# MSP430FR2355 register map
Vendor: msp430gen; File version: v0.4.0-28-gb0087ce-dirty
Registers are 16-bit, read-write, reset 0x0 unless marked. A register's access mark holds for its fields unless they carry their own. Offsets are from the block's base; [hi:lo] are bit positions.

## P3
Base 0x00000220
0x00 P3IN 8-bit — Port 3 Input
0x02 P3OUT 8-bit — Port 3 Output
0x04 P3DIR 8-bit — Port 3 Direction
0x06 P3REN 8-bit — Port 3 Resistor Enable
0x0A P3SEL0 8-bit — Port 3 Select 0
0x0C P3SEL1 8-bit — Port 3 Select 1
0x0E P3IV — Port 3 Interrupt Vector Register
  [15:0] P3IV ro — Port 3 interrupt vector value
    0=NONE (No interrupt pending); 2=IFG0 (Interrupt Source: Port x.0 interrupt; Interrupt Flag: PxIFG.0; Interrupt Priority: Highest); 4=IFG1 (Interrupt Source: Port x.1 interrupt; Interrupt Flag: PxIFG.1); 6=IFG2 (Interrupt Source: Port x.2 interrupt; Interrupt Flag: PxIFG.2); 8=IFG3 (Interrupt Source: Port x.3 interrupt; Interrupt Flag: PxIFG.3); 10=IFG4 (Interrupt Source: Port x.4 interrupt; Interrupt Flag: PxIFG.4); 12=IFG5 (Interrupt Source: Port x.5 interrupt; Interrupt Flag: PxIFG.5); 14=IFG6 (Interrupt Source: Port x.6 interrupt; Interrupt Flag: PxIFG.6); 16=IFG7 (Interrupt Source: Port x.7 interrupt; Interrupt Flag: PxIFG.7; Interrupt Priority: Lowest)
0x16 P3SELC 8-bit — Port 3 Complement Select
0x18 P3IES 8-bit — Port 3 Interrupt Edge Select
0x1A P3IE 8-bit — Port 3 Interrupt Enable
0x1C P3IFG 8-bit — Port 3 Interrupt Flag

## P4
Base 0x00000220
0x01 P4IN 8-bit — Port 4 Input
0x03 P4OUT 8-bit — Port 4 Output
0x05 P4DIR 8-bit — Port 4 Direction
0x07 P4REN 8-bit — Port 4 Resistor Enable
0x0B P4SEL0 8-bit — Port 4 Select 0
0x0D P4SEL1 8-bit — Port 4 Select 1
0x17 P4SELC 8-bit — Port 4 Complement Select
0x19 P4IES 8-bit — Port 4 Interrupt Edge Select
0x1B P4IE 8-bit — Port 4 Interrupt Enable
0x1D P4IFG 8-bit — Port 4 Interrupt Flag
0x1E P4IV — Port 4 Interrupt Vector Register
  [15:0] P4IV ro — Port 4 interrupt vector value
    0=NONE (No interrupt pending); 2=IFG0 (Interrupt Source: Port x.0 interrupt; Interrupt Flag: PxIFG.0; Interrupt Priority: Highest); 4=IFG1 (Interrupt Source: Port x.1 interrupt; Interrupt Flag: PxIFG.1); 6=IFG2 (Interrupt Source: Port x.2 interrupt; Interrupt Flag: PxIFG.2); 8=IFG3 (Interrupt Source: Port x.3 interrupt; Interrupt Flag: PxIFG.3); 10=IFG4 (Interrupt Source: Port x.4 interrupt; Interrupt Flag: PxIFG.4); 12=IFG5 (Interrupt Source: Port x.5 interrupt; Interrupt Flag: PxIFG.5); 14=IFG6 (Interrupt Source: Port x.6 interrupt; Interrupt Flag: PxIFG.6); 16=IFG7 (Interrupt Source: Port x.7 interrupt; Interrupt Flag: PxIFG.7; Interrupt Priority: Lowest)

## P5
Base 0x00000240
0x00 P5IN 8-bit — Port 5 Input
0x02 P5OUT 8-bit — Port 5 Output
0x04 P5DIR 8-bit — Port 5 Direction
0x06 P5REN 8-bit — Port 5 Resistor Enable
0x0A P5SEL0 8-bit — Port 5 Select 0
0x0C P5SEL1 8-bit — Port 5 Select 1
0x16 P5SELC 8-bit — Port 5 Complement Select

## P6
Base 0x00000240
0x01 P6IN 8-bit — Port 6 Input
0x03 P6OUT 8-bit — Port 6 Output
0x05 P6DIR 8-bit — Port 6 Direction
0x07 P6REN 8-bit — Port 6 Resistor Enable
0x0B P6SEL0 8-bit — Port 6 Select 0
0x0D P6SEL1 8-bit — Port 6 Select 1
0x17 P6SELC 8-bit — Port 6 Complement Select

## SFR
Base 0x00000100
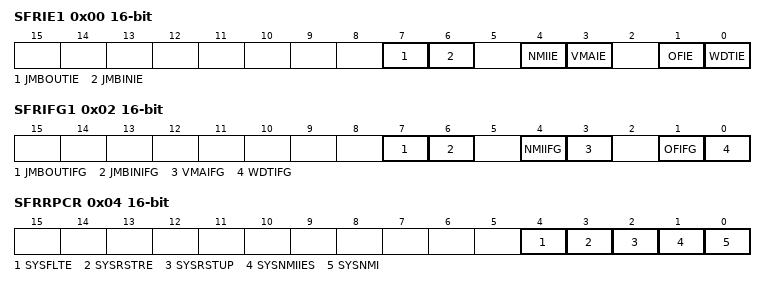
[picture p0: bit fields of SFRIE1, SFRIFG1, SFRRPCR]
0x00 SFRIE1 — Interrupt Enable
  [all] fields
    0=DISABLE (Interrupts disabled); 1=ENABLE (Interrupts enabled)
  [7] JMBOUTIE — JTAG mailbox output interrupt enable
  [6] JMBINIE — JTAG mailbox input interrupt enable
  [4] NMIIE — NMI pin interrupt enable
  [3] VMAIE — Vacant memory access interrupt enable
  [1] OFIE — Oscillator fault interrupt enable
  [0] WDTIE — Watchdog timer interrupt enable
0x02 SFRIFG1 — Interrupt Flag
  [7] JMBOUTIFG — JTAG mailbox output interrupt flag
    0=No interrupt pending. When in 16-bit mode (JMBMODE = 0), this bit is cleared automatically when JMBO0 has been written with a new message to the JTAG module by the CPU. When in 32-bit mode (JMBMODE = 1), this bit is cleared automatically when both JMBO0 and JMBO1 have been written with new messages to the JTAG module by the CPU. This bit is also cleared when the associated vector in SYSUNIV has been read.; 1=Interrupt pending. JMBO registers are ready for new messages. In 16-bit mode (JMBMODE = 0), JMBO0 has been received by the JTAG module and is ready for a new message from the CPU. In 32-bit mode (JMBMODE = 1), JMBO0 and JMBO1 have been received by the JTAG module and are ready for new messages from the CPU.
  [6] JMBINIFG — JTAG mailbox input interrupt flag
    0=No interrupt pending. When in 16-bit mode (JMBMODE = 0), this bit is cleared automatically when JMBI0 is read by the CPU. When in 32-bit mode (JMBMODE = 1), this bit is cleared automatically when both JMBI0 and JMBI1 have been read by the CPU. This bit is also cleared when the associated vector in SYSUNIV has been read; 1=Interrupt pending. A message is waiting in the JMBIN registers. In 16-bit mode (JMBMODE = 0) when JMBI0 has been written by the JTAG module. In 32-bit mode (JMBMODE = 1) when JMBI0 and JMBI1 have been written by the JTAG module.
  [4] NMIIFG — NMI pin interrupt flag
    0=No interrupt pending; 1=Interrupt pending
  [3] VMAIFG — Vacant memory access interrupt flag
    0=No interrupt pending; 1=Interrupt pending
  [1] OFIFG — Oscillator fault interrupt flag
    0=No interrupt pending; 1=Interrupt pending
  [0] WDTIFG — Watchdog timer interrupt flag
    0=No interrupt pending; 1=Interrupt pending
0x04 SFRRPCR — Reset Pin Control
  [4] SYSFLTE — Reset pin filter enable
    0=DISABLED (Reset pin filter disabled); 1=ENABLED (Reset pin filter enabled)
  [3] SYSRSTRE — Reset pin resistor enable
    0=DISABLE (Pullup or pulldown resistor at the RST/NMI pin is disabled); 1=ENABLE (Pullup or pulldown resistor at the RST/NMI pin is enabled)
  [2] SYSRSTUP — Reset resistor pin pullup or pulldown
    0=PULLDOWN (Pulldown is selected); 1=PULLUP (Pullup is selected)
  [1] SYSNMIIES — NMI edge select
    0=RISING (NMI on rising edge); 1=FALLING (NMI on falling edge)
  [0] SYSNMI — NMI select
    0=RESET (Reset function); 1=NMI (NMI function)
